AUTOSAR XML (schema 4-2-2)
package /ComponentTypes
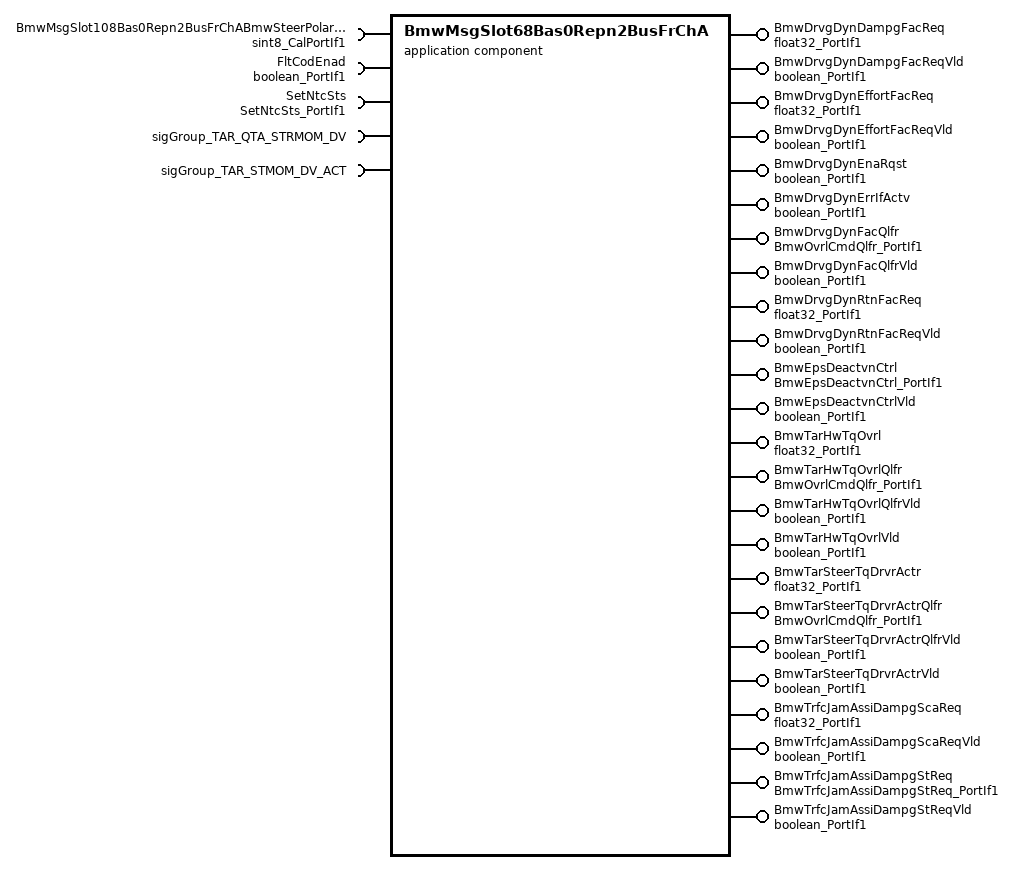
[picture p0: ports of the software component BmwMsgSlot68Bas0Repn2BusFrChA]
  application sw component type BmwMsgSlot68Bas0Repn2BusFrChA
    24 x provide port:
      BmwDrvgDynDampgFacReq: nonqueued-sender-com-spec{data-element=Val, init-value=1}, provided-interface=float32_PortIf1
      BmwDrvgDynDampgFacReqVld: nonqueued-sender-com-spec{data-element=Logl, init-value=0}, provided-interface=boolean_PortIf1
      BmwDrvgDynEffortFacReq: nonqueued-sender-com-spec{data-element=Val, init-value=1}, provided-interface=float32_PortIf1
      BmwDrvgDynEffortFacReqVld: nonqueued-sender-com-spec{data-element=Logl, init-value=0}, provided-interface=boolean_PortIf1
      BmwDrvgDynEnaRqst: nonqueued-sender-com-spec{data-element=Logl, init-value=0}, provided-interface=boolean_PortIf1
      BmwDrvgDynErrIfActv: nonqueued-sender-com-spec{data-element=Logl, init-value=0}, provided-interface=boolean_PortIf1
      BmwDrvgDynFacQlfr: nonqueued-sender-com-spec{data-element=Val, init-value=15}, provided-interface=BmwOvrlCmdQlfr_PortIf1
      BmwDrvgDynFacQlfrVld: nonqueued-sender-com-spec{data-element=Logl, init-value=0}, provided-interface=boolean_PortIf1
      BmwDrvgDynRtnFacReq: nonqueued-sender-com-spec{data-element=Val, init-value=1}, provided-interface=float32_PortIf1
      BmwDrvgDynRtnFacReqVld: nonqueued-sender-com-spec{data-element=Logl, init-value=0}, provided-interface=boolean_PortIf1
      BmwEpsDeactvnCtrl: nonqueued-sender-com-spec{data-element=Val, init-value=15}, provided-interface=BmwEpsDeactvnCtrl_PortIf1
      BmwEpsDeactvnCtrlVld: nonqueued-sender-com-spec{data-element=Logl, init-value=0}, provided-interface=boolean_PortIf1
      BmwTarHwTqOvrl: nonqueued-sender-com-spec{data-element=Val, init-value=0}, provided-interface=float32_PortIf1
      BmwTarHwTqOvrlQlfr: nonqueued-sender-com-spec{data-element=Val, init-value=15}, provided-interface=BmwOvrlCmdQlfr_PortIf1
      BmwTarHwTqOvrlQlfrVld: nonqueued-sender-com-spec{data-element=Logl, init-value=0}, provided-interface=boolean_PortIf1
      BmwTarHwTqOvrlVld: nonqueued-sender-com-spec{data-element=Logl, init-value=0}, provided-interface=boolean_PortIf1
      BmwTarSteerTqDrvrActr: nonqueued-sender-com-spec{data-element=Val, init-value=0}, provided-interface=float32_PortIf1
      BmwTarSteerTqDrvrActrQlfr: nonqueued-sender-com-spec{data-element=Val, init-value=15}, provided-interface=BmwOvrlCmdQlfr_PortIf1
      BmwTarSteerTqDrvrActrQlfrVld: nonqueued-sender-com-spec{data-element=Logl, init-value=0}, provided-interface=boolean_PortIf1
      BmwTarSteerTqDrvrActrVld: nonqueued-sender-com-spec{data-element=Logl, init-value=0}, provided-interface=boolean_PortIf1
      BmwTrfcJamAssiDampgScaReq: nonqueued-sender-com-spec{data-element=Val, init-value=0}, provided-interface=float32_PortIf1
      BmwTrfcJamAssiDampgScaReqVld: nonqueued-sender-com-spec{data-element=Logl, init-value=0}, provided-interface=boolean_PortIf1
      BmwTrfcJamAssiDampgStReq: nonqueued-sender-com-spec{data-element=Val, init-value=1}, provided-interface=BmwTrfcJamAssiDampgStReq_PortIf1
      BmwTrfcJamAssiDampgStReqVld: nonqueued-sender-com-spec{data-element=Logl, init-value=0}, provided-interface=boolean_PortIf1
    5 x require port:
      BmwMsgSlot108Bas0Repn2BusFrChABmwSteerPolarity: parameter-require-com-spec{init-value=-1, parameter=Val}, required-interface=sint8_CalPortIf1
      FltCodEnad: nonqueued-receiver-com-spec{data-element=Logl, filter=data-filter-type=ALWAYS, init-value=1}, required-interface=boolean_PortIf1
      SetNtcSts: client-com-spec=Oper, required-interface=SetNtcSts_PortIf1
      sigGroup_TAR_QTA_STRMOM_DV: nonqueued-receiver-com-spec{data-element=sigGroup_TAR_QTA_STRMOM_DV, uses-end-to-end-protection=true, alive-timeout=0.015, enable-update=true, filter=data-filter-type=ALWAYS, init-value=fields=[FACT_DMPNG_STMOM_FTAX:0, QU_TAR_QTA_STMOM_DV:15, ALIV_TAR_QTA_STMOM_DV:15, QU_TAR_FACT_STMOM_FTAX:15, CTR_DEAC_EPS_FNS:15, FACT_CTRR_STMOM_FTAX:0, TAR_QTA_STMOM_DV_dummy_12_15:0, FACT_ASS_STMOM_FTAX:0, TAR_QTA_STMOM_DV:2000, CRC_TAR_QTA_STMOM_DV:0]}, required-interface=sigGroup_TAR_QTA_STRMOM_DV
      sigGroup_TAR_STMOM_DV_ACT: nonqueued-receiver-com-spec{data-element=sigGroup_TAR_STMOM_DV_ACT, uses-end-to-end-protection=true, alive-timeout=0.015, enable-update=true, filter=data-filter-type=ALWAYS, init-value=fields=[TAR_STMOM_DV_ACT_dummy_12_15:0, TAR_STMOM_DV_ACT_dummy_32_51:0, QU_TAR_DMPNG_ADDON_STMOM_FTAX:15, FACT_DMPNG_ADDON_STMOM_FTAX:255, TAR_STMOM_DV_ACT:2000, CRC_TAR_STMOM_DV_ACT:255, QU_TAR_STMOM_DV_ACT:15, ALIV_TAR_STMOM_DV_ACT:15]}, required-interface=sigGroup_TAR_STMOM_DV_ACT
    behavior BmwMsgSlot68Bas0Repn2BusFrChA_InternalBehavior
      ar-typed-per-instance-memorys:
        64 x data, all with sw-calibration-access=READ-ONLY:
          BmwDrvgDynDampgFacReqPrev: type=float32
          BmwDrvgDynDampgFacReqVldPrev: type=boolean
          BmwDrvgDynEffortFacReqPrev: type=float32
          BmwDrvgDynEffortFacReqVldPrev: type=boolean
          BmwDrvgDynEnaReqPrev: type=boolean
          BmwDrvgDynErrIfActvPrev: type=boolean
          BmwDrvgDynFacQlfrPrev: type=BmwOvrlCmdQlfr1
          BmwDrvgDynFacQlfrVldPrev: type=boolean
          BmwDrvgDynRtnFacReqPrev: type=float32
          BmwDrvgDynRtnFacReqVldPrev: type=boolean
          BmwEpsDeactvnCtrlPrev: type=BmwEpsDeactvnCtrl1
          BmwEpsDeactvnCtrlVldPrev: type=boolean
          BmwTarHwTqOvrlPrev: type=float32
          BmwTarHwTqOvrlQlfPrev: type=BmwOvrlCmdQlfr1
          BmwTarHwTqOvrlQlfrVldPrev: type=boolean
          BmwTarHwTqOvrlVldPrev: type=boolean
          BmwTarSteerTqDrvrActrPrev: type=float32
          BmwTarSteerTqDrvrActrQlfrPrev: type=BmwOvrlCmdQlfr1
          BmwTarSteerTqDrvrActrQlfrVldPrev: type=boolean
          BmwTarSteerTqDrvrActrVldPrev: type=boolean
          BmwTrfcJamAssiDampgScaReqPrev: type=float32
          BmwTrfcJamAssiDampgScaReqVldPrev: type=boolean
          BmwTrfcJamAssiDampgStReqPrev: type=BmwTrfcJamAssiDampgStReq1
          BmwTrfcJamAssiDampgStReqVldPrev: type=boolean
          CtrDeacEpsFnsFaild: type=uint8
          CtrDeacEpsFnsPassd: type=uint8
          FactAssStmomFtaxFaild: type=uint8
          FactAssStmomFtaxPassd: type=uint8
          FactCtrrStmomFtaxFaild: type=uint8
          FactCtrrStmomFtaxPassd: type=uint8
          FactDmpngAddonStmomFtaxFaild: type=uint8
          FactDmpngAddonStmomFtaxPassd: type=uint8
          FactDmpngStmomFtaxFaild: type=uint8
          FactDmpngStmomFtaxPassd: type=uint8
          QuTarDmpngAddonStmomFtaxFaild: type=uint8
          QuTarDmpngAddonStmomFtaxPassd: type=uint8
          QuTarFactStmomFtaxFaild: type=uint8
          QuTarFactStmomFtaxPassd: type=uint8
          QuTarQtaStmomDvFaild: type=uint8
          QuTarQtaStmomDvPassd: type=uint8
          QuTarStmomDvActFaild: type=uint8
          QuTarStmomDvActPassd: type=uint8
          TarQtaStmomDvFaild: type=uint8
          TarQtaStmomDvPassd: type=uint8
          TarQtaStrmomDvAliveCntFaild: type=uint8
          TarQtaStrmomDvAliveCntPassd: type=uint8
          TarQtaStrmomDvArcVld: type=boolean
          TarQtaStrmomDvCRCFaild: type=uint8
          TarQtaStrmomDvCRCPassd: type=uint8
          TarQtaStrmomDvMissFaild: type=uint8
          TarQtaStrmomDvMissPassd: type=uint8
          TarQtaStrmomDvMsgProcd: type=boolean
          TarQtaStrmomDvMsgVld: type=boolean
          TarStmomDvActAliveCntFaild: type=uint8
          TarStmomDvActAliveCntPassd: type=uint8
          TarStmomDvActArcVld: type=boolean
          TarStmomDvActCrcFaild: type=uint8
          TarStmomDvActCrcPassd: type=uint8
          TarStmomDvActFaild: type=uint8
          TarStmomDvActMissFaild: type=uint8
          TarStmomDvActMissPassd: type=uint8
          TarStmomDvActMsgProcd: type=boolean
          TarStmomDvActMsgVld: type=boolean
          TarStmomDvActPassd: type=uint8
      init event BmwMsgSlot68Bas0Repn2BusFrChA_InitEvent: start-on-event=BmwMsgSlot68Bas0Repn2BusFrChAInit1
      data receive error event DRET_TAR_QTA_STRMOM_DV_Miss_sigGroup_TAR_QTA_STRMOM_DV_sigGroup_TAR_QTA_STRMOM_DV: start-on-event=TAR_QTA_STRMOM_DV_Miss, data=sigGroup_TAR_QTA_STRMOM_DV.sigGroup_TAR_QTA_STRMOM_DV
      data received event DRT_TAR_QTA_STRMOM_DV_Rxd_sigGroup_TAR_QTA_STRMOM_DV_sigGroup_TAR_QTA_STRMOM_DV: start-on-event=TAR_QTA_STRMOM_DV_Rxd, data=sigGroup_TAR_QTA_STRMOM_DV.sigGroup_TAR_QTA_STRMOM_DV
      data receive error event DRET_TAR_STMOM_DV_ACT_Miss_sigGroup_TAR_STMOM_DV_ACT_sigGroup_TAR_STMOM_DV_ACT: start-on-event=TAR_STMOM_DV_ACT_Miss, data=sigGroup_TAR_STMOM_DV_ACT.sigGroup_TAR_STMOM_DV_ACT
      data received event DRT_TAR_STMOM_DV_ACT_Rxd_sigGroup_TAR_STMOM_DV_ACT_sigGroup_TAR_STMOM_DV_ACT: start-on-event=TAR_STMOM_DV_ACT_Rxd, data=sigGroup_TAR_STMOM_DV_ACT.sigGroup_TAR_STMOM_DV_ACT
      port-api-options:
        enable-take-address=false, error-handling=NO-TRANSFORMER-ERROR-HANDLING, indirect-api=false, port=BmwDrvgDynDampgFacReq
        enable-take-address=false, error-handling=NO-TRANSFORMER-ERROR-HANDLING, indirect-api=false, port=BmwDrvgDynDampgFacReqVld
        enable-take-address=false, error-handling=NO-TRANSFORMER-ERROR-HANDLING, indirect-api=false, port=BmwDrvgDynEffortFacReq
        enable-take-address=false, error-handling=NO-TRANSFORMER-ERROR-HANDLING, indirect-api=false, port=BmwDrvgDynEffortFacReqVld
        enable-take-address=false, error-handling=NO-TRANSFORMER-ERROR-HANDLING, indirect-api=false, port=BmwDrvgDynEnaRqst
        enable-take-address=false, error-handling=NO-TRANSFORMER-ERROR-HANDLING, indirect-api=false, port=BmwDrvgDynErrIfActv
        enable-take-address=false, error-handling=NO-TRANSFORMER-ERROR-HANDLING, indirect-api=false, port=BmwDrvgDynFacQlfr
        enable-take-address=false, error-handling=NO-TRANSFORMER-ERROR-HANDLING, indirect-api=false, port=BmwDrvgDynFacQlfrVld
        enable-take-address=false, error-handling=NO-TRANSFORMER-ERROR-HANDLING, indirect-api=false, port=BmwDrvgDynRtnFacReq
        enable-take-address=false, error-handling=NO-TRANSFORMER-ERROR-HANDLING, indirect-api=false, port=BmwDrvgDynRtnFacReqVld
        enable-take-address=false, error-handling=NO-TRANSFORMER-ERROR-HANDLING, indirect-api=false, port=BmwEpsDeactvnCtrl
        enable-take-address=false, error-handling=NO-TRANSFORMER-ERROR-HANDLING, indirect-api=false, port=BmwEpsDeactvnCtrlVld
        enable-take-address=false, error-handling=NO-TRANSFORMER-ERROR-HANDLING, indirect-api=false, port=BmwMsgSlot108Bas0Repn2BusFrChABmwSteerPolarity
        enable-take-address=false, error-handling=NO-TRANSFORMER-ERROR-HANDLING, indirect-api=false, port=BmwTarHwTqOvrl
        enable-take-address=false, error-handling=NO-TRANSFORMER-ERROR-HANDLING, indirect-api=false, port=BmwTarHwTqOvrlQlfr
        enable-take-address=false, error-handling=NO-TRANSFORMER-ERROR-HANDLING, indirect-api=false, port=BmwTarHwTqOvrlQlfrVld
        enable-take-address=false, error-handling=NO-TRANSFORMER-ERROR-HANDLING, indirect-api=false, port=BmwTarHwTqOvrlVld
        enable-take-address=false, error-handling=NO-TRANSFORMER-ERROR-HANDLING, indirect-api=false, port=BmwTarSteerTqDrvrActr
        enable-take-address=false, error-handling=NO-TRANSFORMER-ERROR-HANDLING, indirect-api=false, port=BmwTarSteerTqDrvrActrQlfr
        enable-take-address=false, error-handling=NO-TRANSFORMER-ERROR-HANDLING, indirect-api=false, port=BmwTarSteerTqDrvrActrQlfrVld
        enable-take-address=false, error-handling=NO-TRANSFORMER-ERROR-HANDLING, indirect-api=false, port=BmwTarSteerTqDrvrActrVld
        enable-take-address=false, error-handling=NO-TRANSFORMER-ERROR-HANDLING, indirect-api=false, port=BmwTrfcJamAssiDampgScaReq
        enable-take-address=false, error-handling=NO-TRANSFORMER-ERROR-HANDLING, indirect-api=false, port=BmwTrfcJamAssiDampgScaReqVld
        enable-take-address=false, error-handling=NO-TRANSFORMER-ERROR-HANDLING, indirect-api=false, port=BmwTrfcJamAssiDampgStReq
        enable-take-address=false, error-handling=NO-TRANSFORMER-ERROR-HANDLING, indirect-api=false, port=BmwTrfcJamAssiDampgStReqVld
        enable-take-address=false, error-handling=NO-TRANSFORMER-ERROR-HANDLING, indirect-api=false, port=FltCodEnad
        enable-take-address=false, error-handling=NO-TRANSFORMER-ERROR-HANDLING, indirect-api=false, port=SetNtcSts
        enable-take-address=false, error-handling=NO-TRANSFORMER-ERROR-HANDLING, indirect-api=false, port=sigGroup_TAR_QTA_STRMOM_DV
        enable-take-address=false, error-handling=NO-TRANSFORMER-ERROR-HANDLING, indirect-api=false, port=sigGroup_TAR_STMOM_DV_ACT
      5 x runnable:
        BmwMsgSlot68Bas0Repn2BusFrChAInit1
          sync call SC_SetNtcSts_Oper: operation=SetNtcSts.Oper, timeout=0
        TAR_QTA_STRMOM_DV_Miss
          data-receive-point-by-arguments:
            access REC_FltCodEnad_Logl: accessed-variable=FltCodEnad.Logl
            access REC_sigGroup_TAR_QTA_STRMOM_DV_sigGroup_TAR_QTA_STRMOM_DV: accessed-variable=sigGroup_TAR_QTA_STRMOM_DV.sigGroup_TAR_QTA_STRMOM_DV
          data-send-points:
            11 x access:
              SEND_BmwDrvgDynDampgFacReq_Val: accessed-variable=BmwDrvgDynDampgFacReq.Val
              SEND_BmwDrvgDynEffortFacReq_Val: accessed-variable=BmwDrvgDynEffortFacReq.Val
              SEND_BmwDrvgDynEnaRqst_Logl: accessed-variable=BmwDrvgDynEnaRqst.Logl
              SEND_BmwDrvgDynErrIfActv_Logl: accessed-variable=BmwDrvgDynErrIfActv.Logl
              SEND_BmwDrvgDynFacQlfr_Val: accessed-variable=BmwDrvgDynFacQlfr.Val
              SEND_BmwDrvgDynFacQlfrVld_Logl: accessed-variable=BmwDrvgDynFacQlfrVld.Logl
              SEND_BmwDrvgDynRtnFacReq_Val: accessed-variable=BmwDrvgDynRtnFacReq.Val
              SEND_BmwEpsDeactvnCtrl_Val: accessed-variable=BmwEpsDeactvnCtrl.Val
              SEND_BmwTarHwTqOvrl_Val: accessed-variable=BmwTarHwTqOvrl.Val
              SEND_BmwTarHwTqOvrlQlfr_Val: accessed-variable=BmwTarHwTqOvrlQlfr.Val
              SEND_BmwTarHwTqOvrlQlfrVld_Logl: accessed-variable=BmwTarHwTqOvrlQlfrVld.Logl
          sync call SC_SetNtcSts_Oper: operation=SetNtcSts.Oper, timeout=0
        TAR_QTA_STRMOM_DV_Rxd
          data-receive-point-by-arguments:
            access REC_FltCodEnad_Logl: accessed-variable=FltCodEnad.Logl
            access REC_sigGroup_TAR_QTA_STRMOM_DV_sigGroup_TAR_QTA_STRMOM_DV: accessed-variable=sigGroup_TAR_QTA_STRMOM_DV.sigGroup_TAR_QTA_STRMOM_DV
          data-send-points:
            11 x access:
              SEND_BmwDrvgDynDampgFacReq_Val: accessed-variable=BmwDrvgDynDampgFacReq.Val
              SEND_BmwDrvgDynEffortFacReq_Val: accessed-variable=BmwDrvgDynEffortFacReq.Val
              SEND_BmwDrvgDynEnaRqst_Logl: accessed-variable=BmwDrvgDynEnaRqst.Logl
              SEND_BmwDrvgDynErrIfActv_Logl: accessed-variable=BmwDrvgDynErrIfActv.Logl
              SEND_BmwDrvgDynFacQlfr_Val: accessed-variable=BmwDrvgDynFacQlfr.Val
              SEND_BmwDrvgDynFacQlfrVld_Logl: accessed-variable=BmwDrvgDynFacQlfrVld.Logl
              SEND_BmwDrvgDynRtnFacReq_Val: accessed-variable=BmwDrvgDynRtnFacReq.Val
              SEND_BmwEpsDeactvnCtrl_Val: accessed-variable=BmwEpsDeactvnCtrl.Val
              SEND_BmwTarHwTqOvrl_Val: accessed-variable=BmwTarHwTqOvrl.Val
              SEND_BmwTarHwTqOvrlQlfr_Val: accessed-variable=BmwTarHwTqOvrlQlfr.Val
              SEND_BmwTarHwTqOvrlQlfrVld_Logl: accessed-variable=BmwTarHwTqOvrlQlfrVld.Logl
          sync call SC_SetNtcSts_Oper: operation=SetNtcSts.Oper, timeout=0
        TAR_STMOM_DV_ACT_Miss
          data-receive-point-by-arguments:
            access REC_FltCodEnad_Logl: accessed-variable=FltCodEnad.Logl
            access REC_sigGroup_TAR_STMOM_DV_ACT_sigGroup_TAR_STMOM_DV_ACT: accessed-variable=sigGroup_TAR_STMOM_DV_ACT.sigGroup_TAR_STMOM_DV_ACT
          data-send-points:
            9 x access:
              SEND_BmwDrvgDynEnaRqst_Logl: accessed-variable=BmwDrvgDynEnaRqst.Logl
              SEND_BmwDrvgDynErrIfActv_Logl: accessed-variable=BmwDrvgDynErrIfActv.Logl
              SEND_BmwTarSteerTqDrvrActr_Val: accessed-variable=BmwTarSteerTqDrvrActr.Val
              SEND_BmwTarSteerTqDrvrActrQlfr_Val: accessed-variable=BmwTarSteerTqDrvrActrQlfr.Val
              SEND_BmwTarSteerTqDrvrActrQlfrVld_Logl: accessed-variable=BmwTarSteerTqDrvrActrQlfrVld.Logl
              SEND_BmwTrfcJamAssiDampgScaReq_Val: accessed-variable=BmwTrfcJamAssiDampgScaReq.Val
              SEND_BmwTrfcJamAssiDampgScaReqVld_Logl: accessed-variable=BmwTrfcJamAssiDampgScaReqVld.Logl
              SEND_BmwTrfcJamAssiDampgStReq_Val: accessed-variable=BmwTrfcJamAssiDampgStReq.Val
              SEND_BmwTrfcJamAssiDampgStReqVld_Logl: accessed-variable=BmwTrfcJamAssiDampgStReqVld.Logl
          sync call SC_SetNtcSts_Oper: operation=SetNtcSts.Oper, timeout=0
        TAR_STMOM_DV_ACT_Rxd
          data-receive-point-by-arguments:
            access REC_FltCodEnad_Logl: accessed-variable=FltCodEnad.Logl
            access REC_sigGroup_TAR_STMOM_DV_ACT_sigGroup_TAR_STMOM_DV_ACT: accessed-variable=sigGroup_TAR_STMOM_DV_ACT.sigGroup_TAR_STMOM_DV_ACT
          data-send-points:
            9 x access:
              SEND_BmwDrvgDynEnaRqst_Logl: accessed-variable=BmwDrvgDynEnaRqst.Logl
              SEND_BmwDrvgDynErrIfActv_Logl: accessed-variable=BmwDrvgDynErrIfActv.Logl
              SEND_BmwTarSteerTqDrvrActr_Val: accessed-variable=BmwTarSteerTqDrvrActr.Val
              SEND_BmwTarSteerTqDrvrActrQlfr_Val: accessed-variable=BmwTarSteerTqDrvrActrQlfr.Val
              SEND_BmwTarSteerTqDrvrActrQlfrVld_Logl: accessed-variable=BmwTarSteerTqDrvrActrQlfrVld.Logl
              SEND_BmwTrfcJamAssiDampgScaReq_Val: accessed-variable=BmwTrfcJamAssiDampgScaReq.Val
              SEND_BmwTrfcJamAssiDampgScaReqVld_Logl: accessed-variable=BmwTrfcJamAssiDampgScaReqVld.Logl
              SEND_BmwTrfcJamAssiDampgStReq_Val: accessed-variable=BmwTrfcJamAssiDampgStReq.Val
              SEND_BmwTrfcJamAssiDampgStReqVld_Logl: accessed-variable=BmwTrfcJamAssiDampgStReqVld.Logl
          sync call SC_SetNtcSts_Oper: operation=SetNtcSts.Oper, timeout=0
  swc implementation BmwMsgSlot68Bas0Repn2BusFrChA_Implementation: behavior=BmwMsgSlot68Bas0Repn2BusFrChA_InternalBehavior
    code-descriptors:
      code Default: artifact-descriptors=autosar-engineering-object={short-label=Default, category=SWSRC}
